# HDSC_HC32F480 register map
Vendor: HDSC Co.Ltd; Series: ARMCM4; File version: 1.2
CPU: CM0 r0p0, little endian, no MPU, no FPU, 3 interrupt priority bits
Registers are 16-bit, read-write, reset 0x0 unless marked. A register's access mark holds for its fields unless they carry their own. Offsets are from the block's base; [hi:lo] are bit positions; {n}, {i} and the like mark numbered series; 'fields as' and 'values as' point back to an identical list.

## DBGC
Base 0xE0042000
{0x0+4i} AUTHID{i} 32-bit (i=0..2)
0x0C RESV0 32-bit
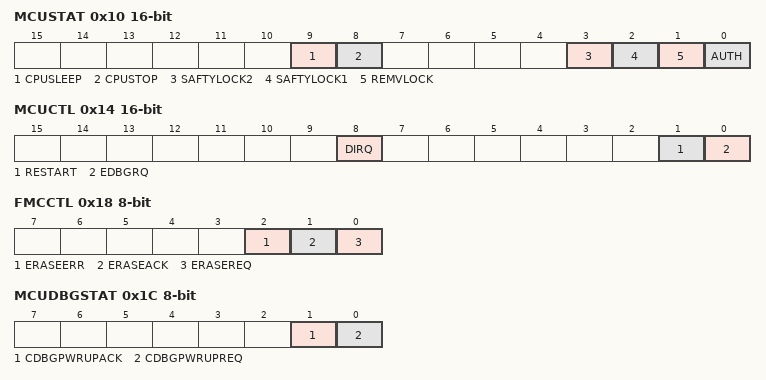
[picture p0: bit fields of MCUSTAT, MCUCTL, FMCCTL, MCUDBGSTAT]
0x10 MCUSTAT
  [9] CPUSLEEP, [8] CPUSTOP, [3] SAFTYLOCK2, [2] SAFTYLOCK1, [1] REMVLOCK, [0] AUTH
0x14 MCUCTL
  [8] DIRQ, [1] RESTART, [0] EDBGRQ
0x18 FMCCTL 8-bit
  [2] ERASEERR, [1] ERASEACK, [0] ERASEREQ
0x1C MCUDBGSTAT 8-bit
  [1] CDBGPWRUPACK, [0] CDBGPWRUPREQ
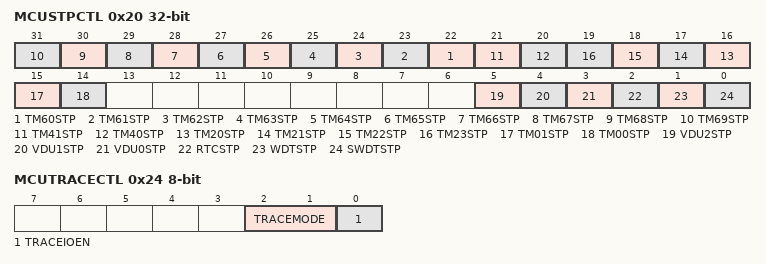
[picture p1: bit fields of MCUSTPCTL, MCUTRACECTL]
0x20 MCUSTPCTL 32-bit
  [n-38] TM{n}STP (n=60..69), [21] TM41STP, [20] TM40STP, [n-4] TM{n}STP (n=20..23), [15] TM01STP, [14] TM00STP, [5] VDU2STP, [4] VDU1STP, [3] VDU0STP, [2] RTCSTP, [1] WDTSTP, [0] SWDTSTP
0x24 MCUTRACECTL 8-bit
  [2:1] TRACEMODE, [0] TRACEIOEN

## DCU0
Base 0x40052000
Same registers: DCU1 0x40052400, DCU2 0x40052800, DCU3 0x40052C00
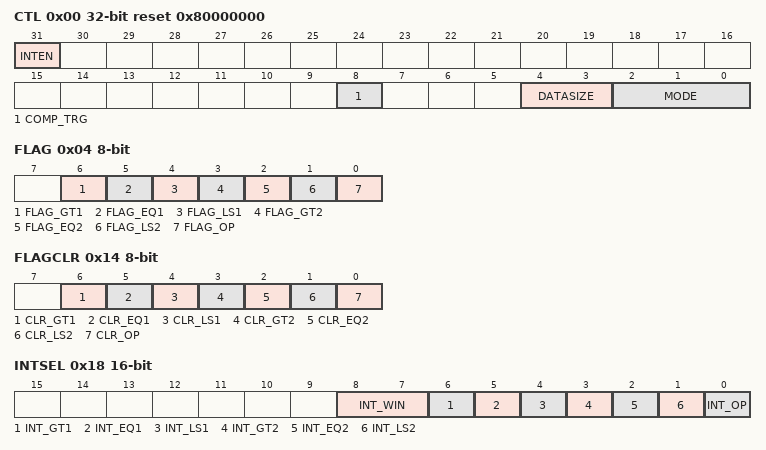
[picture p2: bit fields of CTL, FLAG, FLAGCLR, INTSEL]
0x00 CTL 32-bit reset 0x80000000
  [31] INTEN, [8] COMP_TRG, [4:3] DATASIZE, [2:0] MODE
0x04 FLAG 8-bit ro
  [6] FLAG_GT1, [5] FLAG_EQ1, [4] FLAG_LS1, [3] FLAG_GT2, [2] FLAG_EQ2, [1] FLAG_LS2, [0] FLAG_OP
{0x8+4i} DATA{i} 32-bit (i=0..2)
0x14 FLAGCLR 8-bit wo
  [6] CLR_GT1, [5] CLR_EQ1, [4] CLR_LS1, [3] CLR_GT2, [2] CLR_EQ2, [1] CLR_LS2, [0] CLR_OP
0x18 INTSEL
  [8:7] INT_WIN, [6] INT_GT1, [5] INT_EQ1, [4] INT_LS1, [3] INT_GT2, [2] INT_EQ2, [1] INT_LS2, [0] INT_OP

## DMAC
Base 0x40053000
0x00 EN 32-bit
  [0] EN
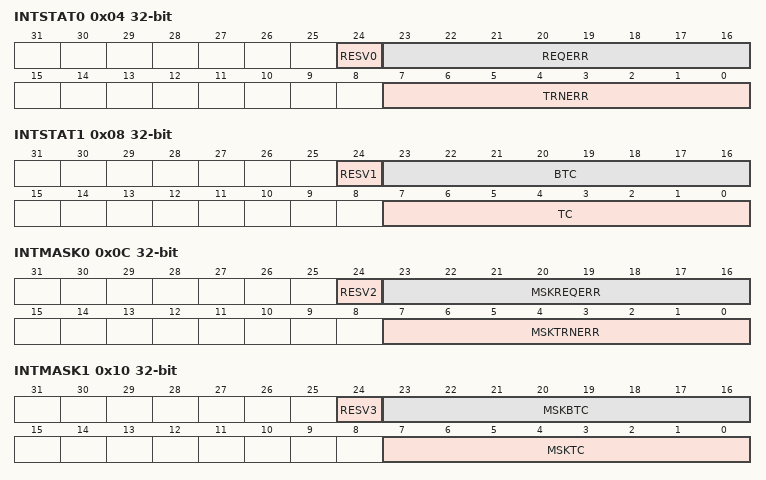
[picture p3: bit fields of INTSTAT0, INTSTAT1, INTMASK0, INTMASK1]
0x04 INTSTAT0 32-bit ro
  [24] RESV0 rw, [23:16] REQERR, [7:0] TRNERR
0x08 INTSTAT1 32-bit ro
  [24] RESV1 rw, [23:16] BTC, [7:0] TC
0x0C INTMASK0 32-bit
  [24] RESV2, [23:16] MSKREQERR, [7:0] MSKTRNERR
0x10 INTMASK1 32-bit
  [24] RESV3, [23:16] MSKBTC, [7:0] MSKTC
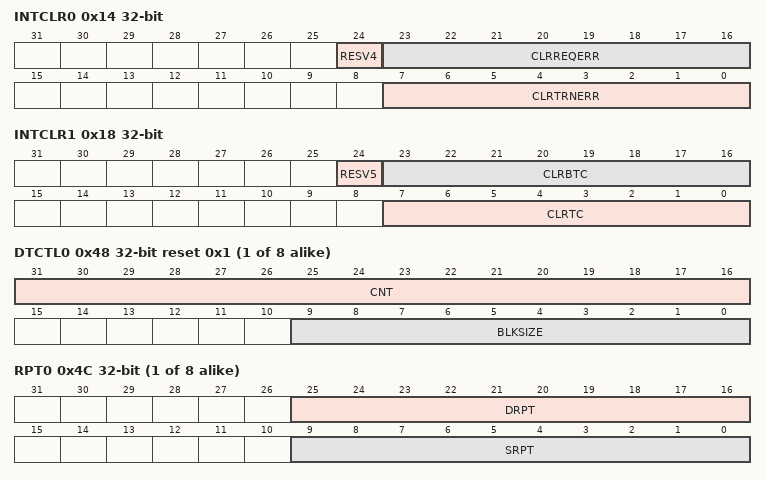
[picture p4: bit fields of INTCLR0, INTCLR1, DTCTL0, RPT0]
0x14 INTCLR0 32-bit wo
  [24] RESV4 rw, [23:16] CLRREQERR, [7:0] CLRTRNERR
0x18 INTCLR1 32-bit wo
  [24] RESV5 rw, [23:16] CLRBTC, [7:0] CLRTC
0x1C CHEN 32-bit (reset mask 0xFF)
{0x40+0x40*i} SAR{i} 32-bit (i=0..7)
{0x44+0x40*i} DAR{i} 32-bit (i=0..7)
{0x48+0x40*i} DTCTL{i} 32-bit reset 0x1 (i=0..7)
  [31:16] CNT, [9:0] BLKSIZE
{0x4C+0x40*i} RPT{i} 32-bit (i=0..7)
  [25:16] DRPT, [9:0] SRPT
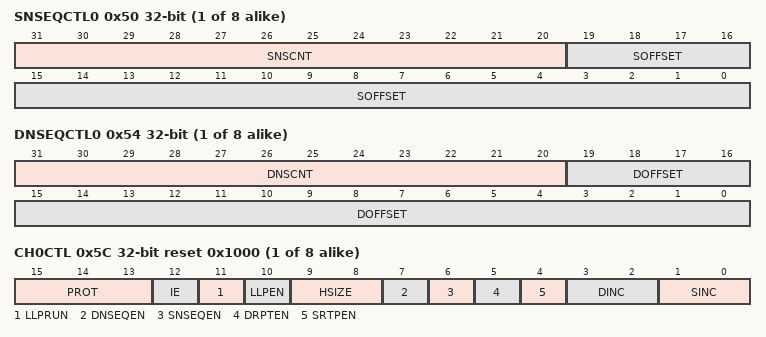
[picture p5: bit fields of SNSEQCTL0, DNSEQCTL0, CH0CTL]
{0x50+0x40*i} SNSEQCTL{i} 32-bit (i=0..7)
  [31:20] SNSCNT, [19:0] SOFFSET
{0x54+0x40*i} DNSEQCTL{i} 32-bit (i=0..7)
  [31:20] DNSCNT, [19:0] DOFFSET
{0x58+0x40*i} LLP{i} 32-bit (i=0..7)
  [31:2] LLP
{0x5C+0x40*i} CH{i}CTL 32-bit reset 0x1000 (i=0..7)
  [15:13] PROT, [12] IE, [11] LLPRUN, [10] LLPEN, [9:8] HSIZE, [7] DNSEQEN, [6] SNSEQEN, [5] DRPTEN, [4] SRTPEN, [3:2] DINC, [1:0] SINC

## EFM
Base 0x40010400
0x00 FAPRT
0x04 FSTP 8-bit
  [0] FSTP
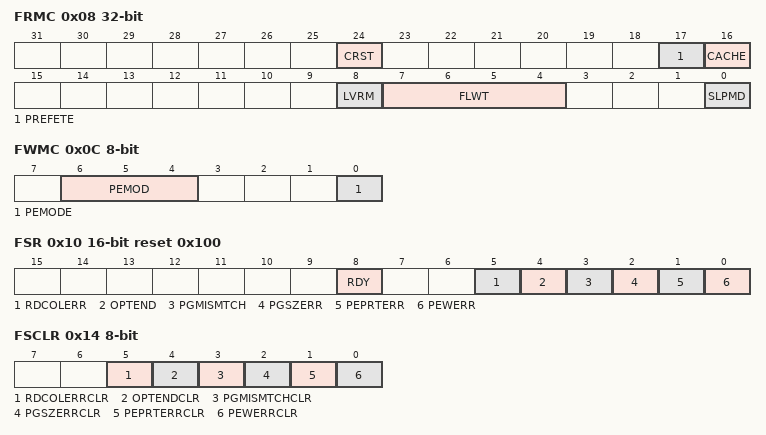
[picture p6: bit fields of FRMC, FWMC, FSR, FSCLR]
0x08 FRMC 32-bit
  [24] CRST, [17] PREFETE, [16] CACHE, [8] LVRM, [7:4] FLWT, [0] SLPMD
0x0C FWMC 8-bit
  [6:4] PEMOD, [0] PEMODE
0x10 FSR ro reset 0x100
  [8] RDY, [5] RDCOLERR, [4] OPTEND, [3] PGMISMTCH, [2] PGSZERR, [1] PEPRTERR, [0] PEWERR
0x14 FSCLR 8-bit
  [5] RDCOLERRCLR, [4] OPTENDCLR, [3] PGMISMTCHCLR, [2] PGSZERRCLR, [1] PEPRTERRCLR, [0] PEWERRCLR
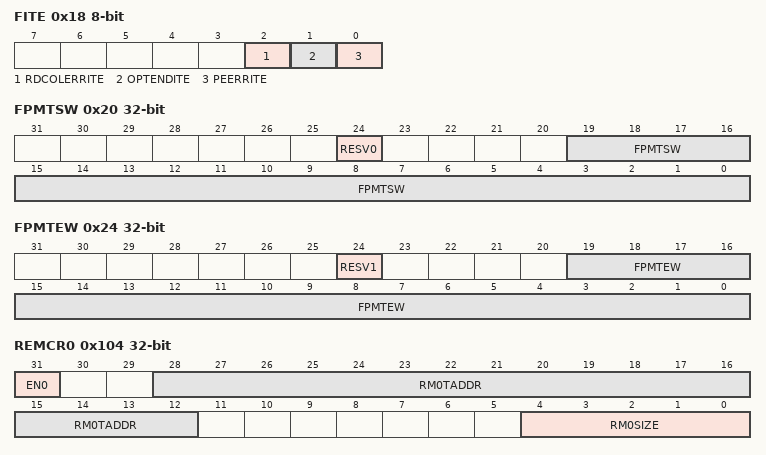
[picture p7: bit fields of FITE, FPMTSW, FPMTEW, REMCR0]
0x18 FITE 8-bit
  [2] RDCOLERRITE, [1] OPTENDITE, [0] PEERRITE
0x1C FSWP 8-bit ro reset 0x1
  [0] FSWP
0x20 FPMTSW 32-bit
  [24] RESV0, [19:0] FPMTSW
0x24 FPMTEW 32-bit
  [24] RESV1, [19:0] FPMTEW
{0x4C+4i} UQID{i} 32-bit ro (i=1..3)
0x100 REMPRT
0x104 REMCR0 32-bit
  [31] EN0, [28:12] RM0TADDR, [4:0] RM0SIZE
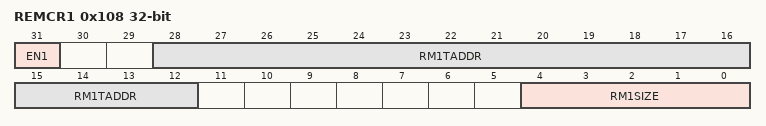
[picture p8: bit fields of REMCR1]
0x108 REMCR1 32-bit
  [31] EN1, [28:12] RM1TADDR, [4:0] RM1SIZE

## EFMD
Base 0x40010000
0x00 DFAPRT
0x04 DFSTP 8-bit
  [0] FSTP
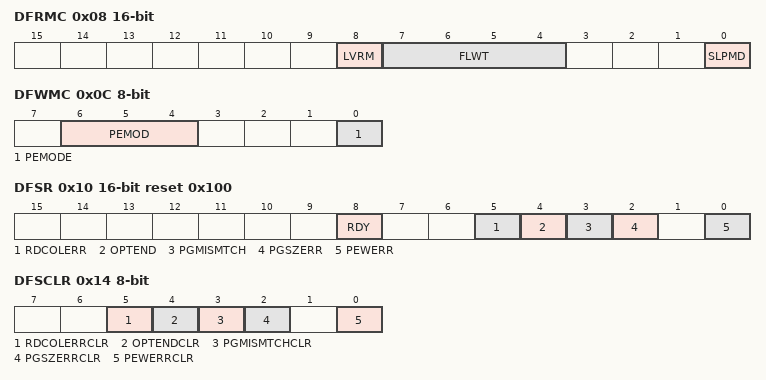
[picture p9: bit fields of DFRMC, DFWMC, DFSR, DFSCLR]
0x08 DFRMC
  [8] LVRM, [7:4] FLWT, [0] SLPMD
0x0C DFWMC 8-bit
  [6:4] PEMOD, [0] PEMODE
0x10 DFSR ro reset 0x100
  [8] RDY, [5] RDCOLERR, [4] OPTEND, [3] PGMISMTCH, [2] PGSZERR, [0] PEWERR
0x14 DFSCLR 8-bit
  [5] RDCOLERRCLR, [4] OPTENDCLR, [3] PGMISMTCHCLR, [2] PGSZERRCLR, [0] PEWERRCLR
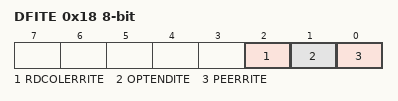
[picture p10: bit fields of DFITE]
0x18 DFITE 8-bit
  [2] RDCOLERRITE, [1] OPTENDITE, [0] PEERRITE

## EMB
Base 0x4001BC00
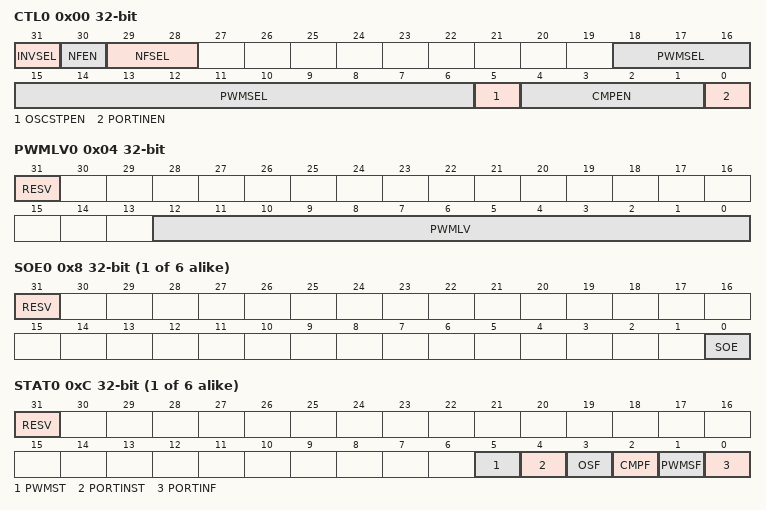
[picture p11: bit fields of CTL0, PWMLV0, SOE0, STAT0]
0x00 CTL0 32-bit
  [31] INVSEL, [30] NFEN, [29:28] NFSEL, [18:6] PWMSEL, [5] OSCSTPEN, [4:1] CMPEN, [0] PORTINEN
0x04 PWMLV0 32-bit
  [31] RESV, [12:0] PWMLV
{0x8+0x20*i} SOE{i} 32-bit (i=0..5)
  [31] RESV, [0] SOE
{0xC+0x20*i} STAT{i} 32-bit ro (i=0..5)
  [31] RESV rw, [5] PWMST, [4] PORTINST, [3] OSF, [2] CMPF, [1] PWMSF, [0] PORTINF
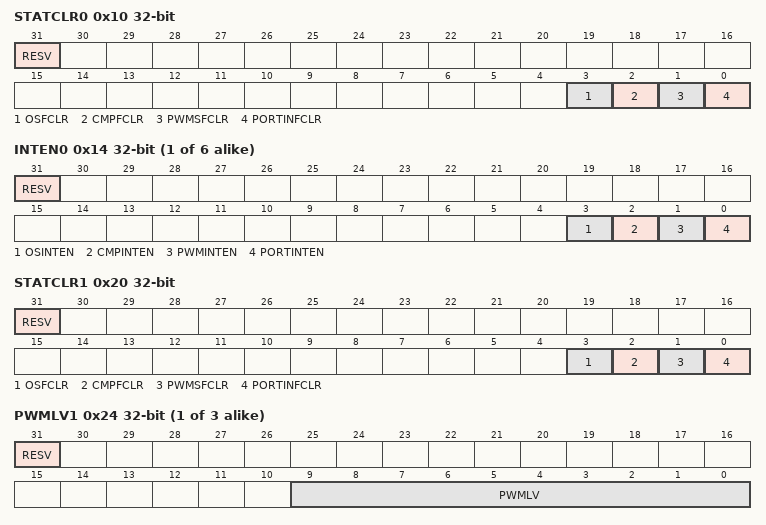
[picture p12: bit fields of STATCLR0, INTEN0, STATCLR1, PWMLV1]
0x10 STATCLR0 32-bit wo
  [31] RESV rw, [3] OSFCLR, [2] CMPFCLR, [1] PWMSFCLR, [0] PORTINFCLR
{0x14+0x20*i} INTEN{i} 32-bit (i=0..5)
  [31] RESV, [3] OSINTEN, [2] CMPINTEN, [1] PWMINTEN, [0] PORTINTEN
0x20 STATCLR1 32-bit wo
  [31] RESV rw, [3] OSFCLR, [2] CMPFCLR, [1] PWMSFCLR, [0] PORTINFCLR
{0x4+0x20*i} PWMLV{i} 32-bit (i=1..3)
  [31] RESV, [9:0] PWMLV
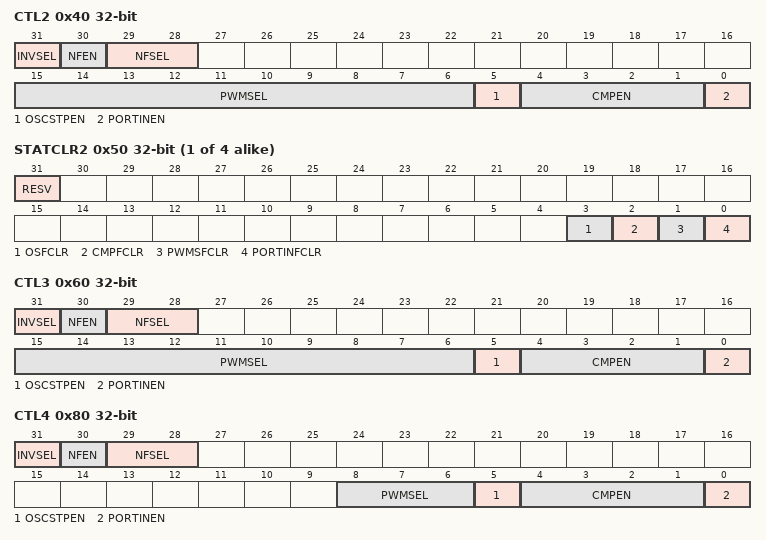
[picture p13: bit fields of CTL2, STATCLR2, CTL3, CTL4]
0x40 CTL2 32-bit
  [31] INVSEL, [30] NFEN, [29:28] NFSEL, [15:6] PWMSEL, [5] OSCSTPEN, [4:1] CMPEN, [0] PORTINEN
{0x10+0x20*i} STATCLR{i} 32-bit wo (i=2..5)
  [31] RESV rw, [3] OSFCLR, [2] CMPFCLR, [1] PWMSFCLR, [0] PORTINFCLR
0x60 CTL3 32-bit
  fields as CTL2
0x80 CTL4 32-bit
  [31] INVSEL, [30] NFEN, [29:28] NFSEL, [8:6] PWMSEL, [5] OSCSTPEN, [4:1] CMPEN, [0] PORTINEN
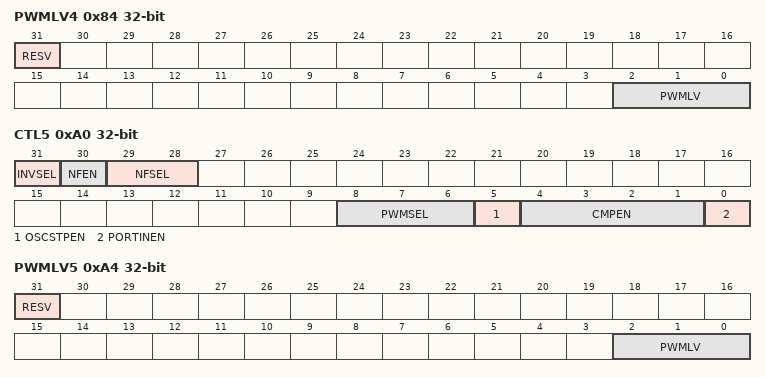
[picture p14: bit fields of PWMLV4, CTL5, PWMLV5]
0x84 PWMLV4 32-bit
  [31] RESV, [2:0] PWMLV
0xA0 CTL5 32-bit
  fields as CTL4
0xA4 PWMLV5 32-bit
  [31] RESV, [2:0] PWMLV
